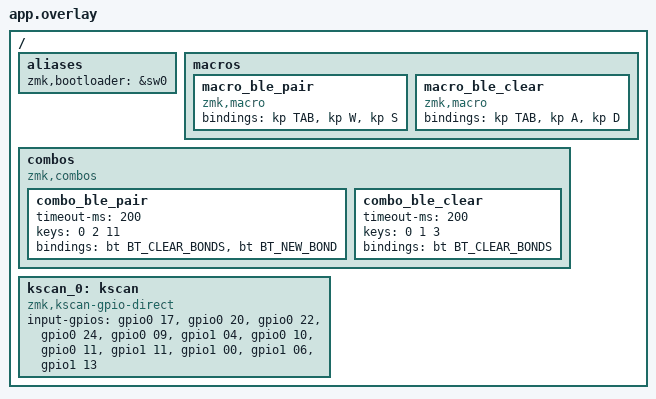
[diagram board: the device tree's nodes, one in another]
/ {
    aliases {
        zmk,bootloader = &sw0;
    };

    macros {
        macro_ble_pair: macro_ble_pair {
            compatible = "zmk,macro";
            bindings = <&kp TAB &kp W &kp S>;
        };
        macro_ble_clear: macro_ble_clear {
            compatible = "zmk,macro";
            bindings = <&kp TAB &kp A &kp D>;
        };
    };

    combos {
        compatible = "zmk,combos";
        combo_ble_pair {
            timeout-ms = <200>;
            keys = <0 2 11>;
            bindings = <&bt BT_CLEAR_BONDS &bt BT_NEW_BOND>;
        };
        combo_ble_clear {
            timeout-ms = <200>;
            keys = <0 1 3>;
            bindings = <&bt BT_CLEAR_BONDS>;
        };
    };

    kscan_0: kscan {
        compatible = "zmk,kscan-gpio-direct";
        input-gpios =
            <&gpio0 17 GPIO_PULL_UP>,  /* 0 W */
            <&gpio0 20 GPIO_PULL_UP>,  /* 1 A */
            <&gpio0 22 GPIO_PULL_UP>,  /* 2 S */
            <&gpio0 24 GPIO_PULL_UP>,  /* 3 D */
            <&gpio0 09 GPIO_PULL_UP>,  /* 4 SPACE */
            <&gpio1 04 GPIO_PULL_UP>,  /* 5 F */
            <&gpio0 10 GPIO_PULL_UP>,  /* 6 E */
            <&gpio0 11 GPIO_PULL_UP>,  /* 7 UP */
            <&gpio1 11 GPIO_PULL_UP>,  /* 8 DOWN */
            <&gpio1 00 GPIO_PULL_UP>,  /* 9 R */
            <&gpio1 06 GPIO_PULL_UP>,  /*10 LALT */
            <&gpio1 13 GPIO_PULL_UP>;  /*11 TAB */
    };
};
